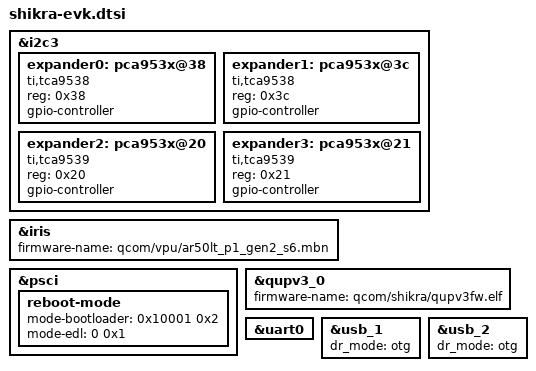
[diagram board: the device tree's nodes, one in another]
// SPDX-License-Identifier: BSD-3-Clause
/*
 * Copyright (c) Qualcomm Technologies, Inc. and/or its subsidiaries.
 */

&i2c3 {
	status = "okay";

	expander0: pca953x@38 {
		compatible = "ti,tca9538";
		reg = <0x38>;
		#gpio-cells = <2>;
		gpio-controller;
	};

	expander1: pca953x@3c {
		compatible = "ti,tca9538";
		reg = <0x3c>;
		#gpio-cells = <2>;
		gpio-controller;
	};

	expander2: pca953x@20 {
		compatible = "ti,tca9539";
		reg = <0x20>;
		#gpio-cells = <2>;
		gpio-controller;
	};

	expander3: pca953x@21 {
		compatible = "ti,tca9539";
		reg = <0x21>;
		#gpio-cells = <2>;
		gpio-controller;
	};
};

&iris {
	firmware-name = "qcom/vpu/ar50lt_p1_gen2_s6.mbn";

	status = "okay";
};

&psci {
	reboot-mode {
		mode-bootloader = <0x10001 0x2>;
		mode-edl = <0 0x1>;
	};
};

&qupv3_0 {
	firmware-name = "qcom/shikra/qupv3fw.elf";
	status = "okay";
};

&uart0 {
	status = "okay";
};

&usb_1 {
	dr_mode = "otg";

	status = "okay";
};

&usb_2 {
	dr_mode = "otg";

	status = "okay";
};
